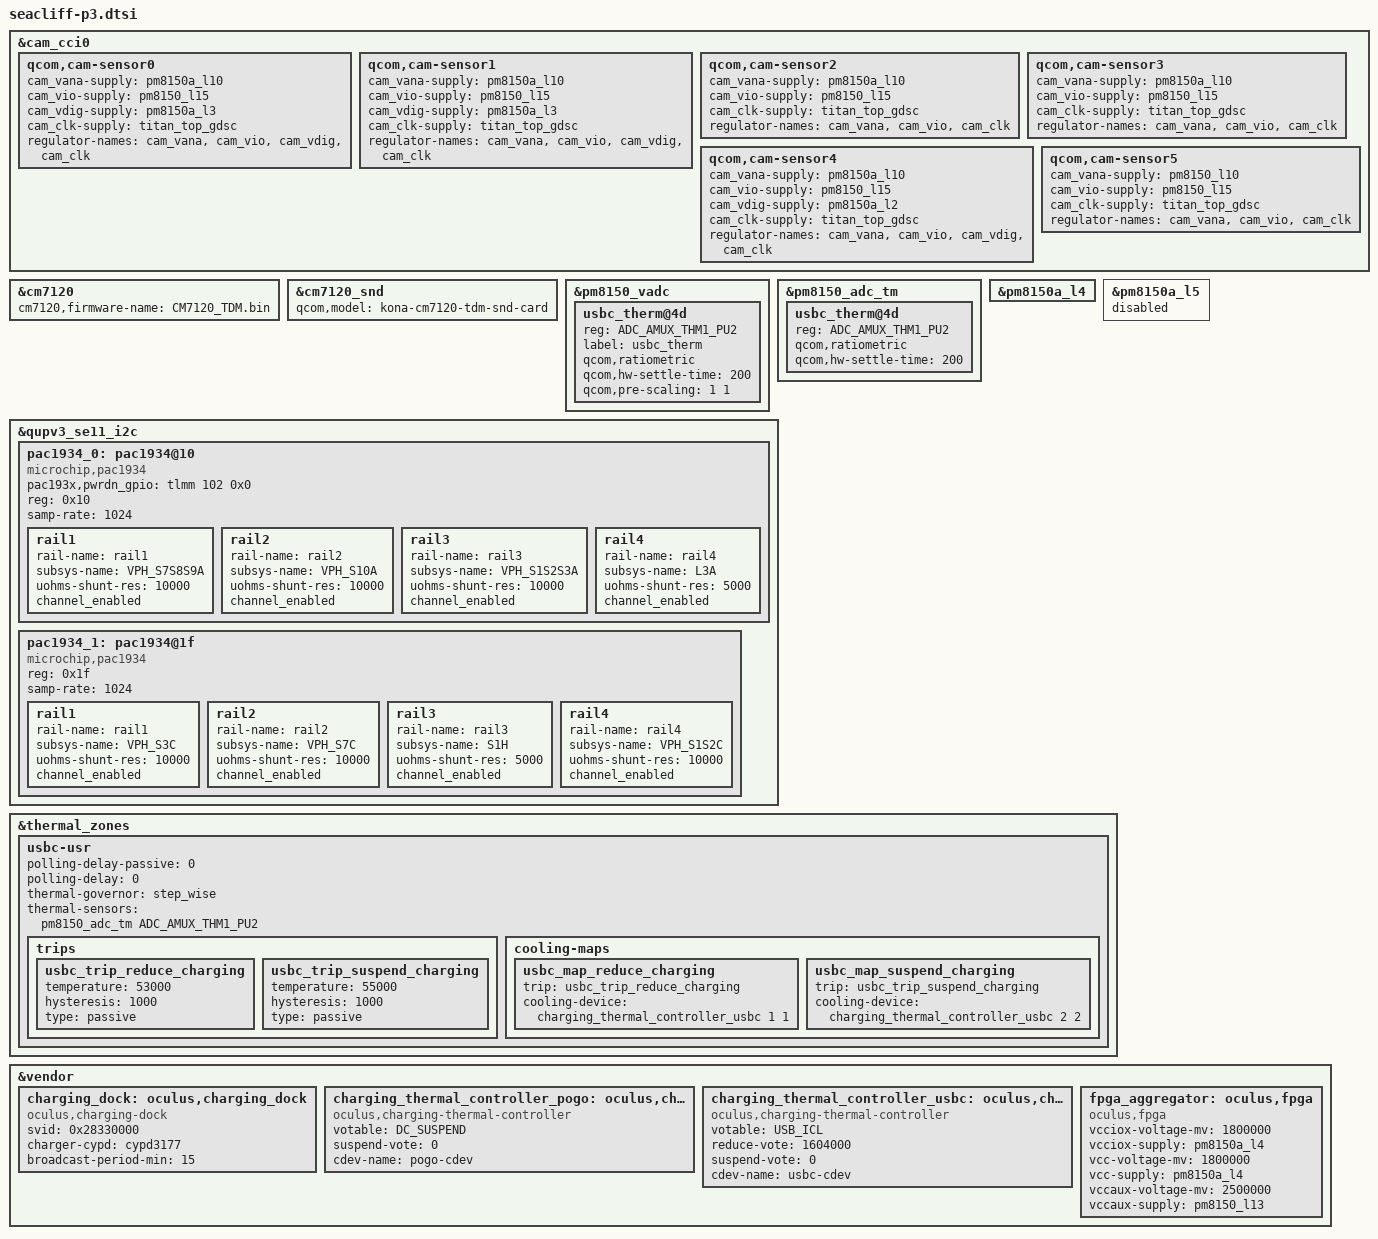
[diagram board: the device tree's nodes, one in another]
// SPDX-License-Identifier: GPL-2.0

#include "seacliff-non-pop.dtsi"

&cam_cci0 {
	qcom,cam-sensor0 {
		cam_vana-supply = <&pm8150a_l10>;
		cam_vio-supply = <&pm8150_l15>;
		cam_vdig-supply = <&pm8150a_l3>;
		cam_clk-supply = <&titan_top_gdsc>;
		regulator-names = "cam_vana", "cam_vio", "cam_vdig",
			"cam_clk";
	};

	qcom,cam-sensor1 {
		cam_vana-supply = <&pm8150a_l10>;
		cam_vio-supply = <&pm8150_l15>;
		cam_vdig-supply = <&pm8150a_l3>;
		cam_clk-supply = <&titan_top_gdsc>;
		regulator-names = "cam_vana", "cam_vio", "cam_vdig",
			"cam_clk";
	};

	qcom,cam-sensor2 {
		cam_vana-supply = <&pm8150a_l10>;
		cam_vio-supply = <&pm8150_l15>;
		cam_clk-supply = <&titan_top_gdsc>;
		regulator-names = "cam_vana", "cam_vio",
			"cam_clk";
	};

	qcom,cam-sensor3 {
		cam_vana-supply = <&pm8150a_l10>;
		cam_vio-supply = <&pm8150_l15>;
		cam_clk-supply = <&titan_top_gdsc>;
		regulator-names = "cam_vana", "cam_vio",
			"cam_clk";
	};

	qcom,cam-sensor4 {
		cam_vana-supply = <&pm8150a_l10>;
		cam_vio-supply = <&pm8150_l15>;
		cam_vdig-supply = <&pm8150a_l2>;
		cam_clk-supply = <&titan_top_gdsc>;
		regulator-names = "cam_vana", "cam_vio", "cam_vdig",
			"cam_clk";
	};

	qcom,cam-sensor5 {
		cam_vana-supply = <&pm8150_l10>;
		cam_vio-supply = <&pm8150_l15>;
		cam_clk-supply = <&titan_top_gdsc>;
		regulator-names = "cam_vana", "cam_vio", "cam_clk";
	};
};

&cm7120 {
	cm7120,firmware-name = "CM7120_TDM.bin";
};

&cm7120_snd {
	qcom,model = "kona-cm7120-tdm-snd-card";
};

&pm8150_vadc {
	usbc_therm@4d {
		reg = <ADC_AMUX_THM1_PU2>;
		label = "usbc_therm";
		qcom,ratiometric;
		qcom,hw-settle-time = <200>;
		qcom,pre-scaling = <1 1>;
	};
};

&pm8150_adc_tm {
	usbc_therm@4d {
		reg = <ADC_AMUX_THM1_PU2>;
		qcom,ratiometric;
		qcom,hw-settle-time = <200>;
	};
};

&pm8150a_l4 {
	status = "ok";
};

&pm8150a_l5 {
	status = "disabled";
};

&qupv3_se11_i2c {
	pac1934_0: pac1934@10 {
		compatible = "microchip,pac1934";
		pac193x,pwrdn_gpio = <&tlmm 102 0x0>;
		reg = <0x10>;
		samp-rate = <1024>;
		status = "okay";

		rail1 {
			rail-name = "rail1";
			subsys-name = "VPH_S7S8S9A";
			uohms-shunt-res = <10000>;
			channel_enabled;
		};

		rail2 {
			rail-name = "rail2";
			subsys-name = "VPH_S10A";
			uohms-shunt-res = <10000>;
			channel_enabled;
		};

		rail3 {
			rail-name = "rail3";
			subsys-name = "VPH_S1S2S3A";
			uohms-shunt-res = <10000>;
			channel_enabled;
		};

		rail4 {
			rail-name = "rail4";
			subsys-name = "L3A";
			uohms-shunt-res = <5000>;
			channel_enabled;
		};
	};

	pac1934_1: pac1934@1f {
		compatible = "microchip,pac1934";
		reg = <0x1f>;
		samp-rate = <1024>;
		status = "okay";

		rail1 {
			rail-name = "rail1";
			subsys-name = "VPH_S3C";
			uohms-shunt-res = <10000>;
			channel_enabled;
		};

		rail2 {
			rail-name = "rail2";
			subsys-name = "VPH_S7C";
			uohms-shunt-res = <10000>;
			channel_enabled;
		};

		rail3 {
			rail-name = "rail3";
			subsys-name = "S1H";
			uohms-shunt-res = <5000>;
			channel_enabled;
		};

		rail4 {
			rail-name = "rail4";
			subsys-name = "VPH_S1S2C";
			uohms-shunt-res = <10000>;
			channel_enabled;
		};
	};
};

&thermal_zones {
	usbc-usr {
		polling-delay-passive = <0>;
		polling-delay = <0>;
		thermal-governor = "step_wise";
		thermal-sensors = <&pm8150_adc_tm ADC_AMUX_THM1_PU2>;
		trips {
			usbc_trip_reduce_charging: usbc_trip_reduce_charging {
				temperature = <53000>;
				hysteresis = <1000>;
				type = "passive";
			};
			usbc_trip_suspend_charging: usbc_trip_suspend_charging {
				temperature = <55000>;
				hysteresis = <1000>;
				type = "passive";
			};
		};
		cooling-maps {
			usbc_map_reduce_charging: usbc_map_reduce_charging {
				trip = <&usbc_trip_reduce_charging>;
				cooling-device = <&charging_thermal_controller_usbc 1 1>;
			};
			usbc_map_suspend_charging: usbc_map_suspend_charging {
				trip = <&usbc_trip_suspend_charging>;
				cooling-device = <&charging_thermal_controller_usbc 2 2>;
			};
		};
	};
};

&vendor {
	charging_dock: oculus,charging_dock {
		status = "ok";
		compatible = "oculus,charging-dock";
		svid = <0x28330000>;
		charger-cypd = <&cypd3177>;
		broadcast-period-min = <15>;
	};

	charging_thermal_controller_pogo: oculus,charging_thermal_controller_pogo {
		status = "ok";
		compatible = "oculus,charging-thermal-controller";
		votable = "DC_SUSPEND";
		suspend-vote = <0>;
		cdev-name = "pogo-cdev";
		#cooling-cells = <2>;
	};

	charging_thermal_controller_usbc: oculus,charging_thermal_controller_usbc {
		status = "ok";
		compatible = "oculus,charging-thermal-controller";
		votable = "USB_ICL";
		reduce-vote = <1604000>;
		suspend-vote = <0>;
		cdev-name = "usbc-cdev";
		#cooling-cells = <2>;
	};

	fpga_aggregator: oculus,fpga {
		status = "ok";
		compatible = "oculus,fpga";
		vcciox-voltage-mv = <1800000>;
		vcciox-supply = <&pm8150a_l4>;
		vcc-voltage-mv = <1800000>;
		vcc-supply = <&pm8150a_l4>;
		vccaux-voltage-mv = <2500000>;
		vccaux-supply = <&pm8150_l13>;
	};
};
